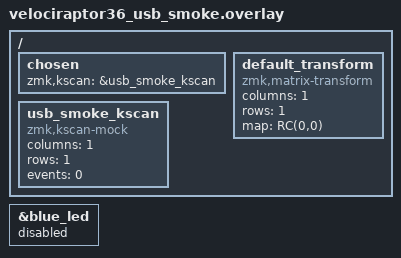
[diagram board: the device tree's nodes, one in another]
/*
 * Copyright (c) 2026
 *
 * SPDX-License-Identifier: MIT
 */

#include <dt-bindings/zmk/matrix_transform.h>

&blue_led {
    status = "disabled";
};

/ {
    chosen {
        zmk,kscan = &usb_smoke_kscan;
    };

    default_transform: default_transform {
        compatible = "zmk,matrix-transform";
        columns = <1>;
        rows = <1>;
        map = <RC(0,0)>;
    };

    usb_smoke_kscan: usb_smoke_kscan {
        compatible = "zmk,kscan-mock";
        columns = <1>;
        rows = <1>;
        events = <0>;
    };
};
